# PIC16F1613 register map
Vendor: Microchip
Registers are 8-bit, read-write, reset 0x0 unless marked. A register's access mark holds for its fields unless they carry their own. Addresses are absolute, and some are shared; only a register's first bit layout is shown; [hi:lo] are bit positions; {n}, {i} and the like mark numbered series.

## SFR
0x00 INDF0 reset not defined — (power-on value xxxxxxxx)
0x01 INDF1 reset not defined — (power-on value xxxxxxxx)
0x02 PCL
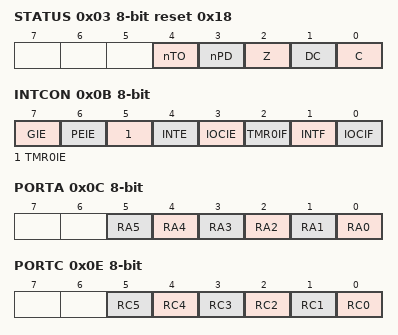
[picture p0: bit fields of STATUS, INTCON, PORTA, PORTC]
0x03 STATUS reset 0x18
  [4] nTO ro, [3] nPD ro, [2] Z, [1] DC, [0] C
0x04 FSR0L
0x05 FSR0H
0x06 FSR1L
0x07 FSR1H
0x08 BSR
  [4:0] BSR
0x09 WREG
  [7:0] WREG0
0x0A PCLATH
  [6:0] PCLATH
0x0B INTCON
  [7] GIE, [6] PEIE, [5] TMR0IE, [4] INTE, [3] IOCIE, [2] TMR0IF, [1] INTF, [0] IOCIF ro
0x0C PORTA reset not defined — (power-on value --xxxxxx)
  [n] RA{n} (n=0..5)
0x0E PORTC reset not defined — (power-on value --xxxxxx)
  [n] RC{n} (n=0..5)
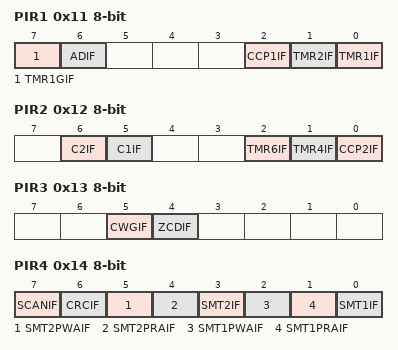
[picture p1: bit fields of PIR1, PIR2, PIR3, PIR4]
0x11 PIR1
  [7] TMR1GIF — Timer1 Gate Interrupt Flag bit
  [6] ADIF — A/D Converter Interrupt Flag bit
  [2] CCP1IF
  [1] TMR2IF — TMR2 to PR2 Match Interrupt Flag bit
  [0] TMR1IF — TMR1 Overflow Interrupt Flag bit
0x12 PIR2
  [6] C2IF — Numerically Controlled Oscillator Flag bit
  [5] C1IF — Numerically Controlled Oscillator Flag bit
  [2] TMR6IF — Numerically Controlled Oscillator Flag bit
  [1] TMR4IF
  [0] CCP2IF
0x13 PIR3
  [5] CWGIF, [4] ZCDIF
0x14 PIR4
  [7] SCANIF, [6] CRCIF, [5] SMT2PWAIF, [4] SMT2PRAIF, [3] SMT2IF, [2] SMT1PWAIF, [1] SMT1PRAIF, [0] SMT1IF
0x15 TMR0 reset not defined — (power-on value xxxxxxxx)
0x16 TMR1L reset not defined — (power-on value xxxxxxxx)
0x17 TMR1H reset not defined — (power-on value xxxxxxxx)
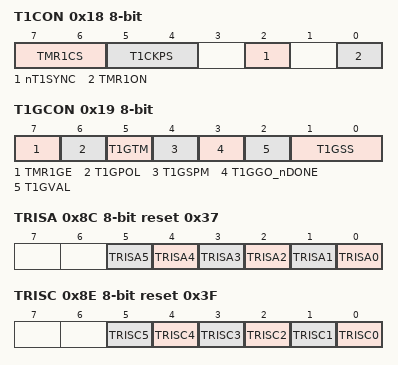
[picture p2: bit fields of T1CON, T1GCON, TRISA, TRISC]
0x18 T1CON
  [7:6] TMR1CS, [5:4] T1CKPS, [2] nT1SYNC, [0] TMR1ON
0x19 T1GCON reset not defined — (power-on value 00000x00)
  [7] TMR1GE, [6] T1GPOL, [5] T1GTM, [4] T1GSPM, [3] T1GGO_nDONE, [2] T1GVAL ro, [1:0] T1GSS
0x8C TRISA reset 0x37 — PORTA Data Direction Control Register
  [n] TRISA{n} (n=0..5)
0x8E TRISC reset 0x3F — PORTC Data Direction Control Register
  [n] TRISC{n} (n=0..5)
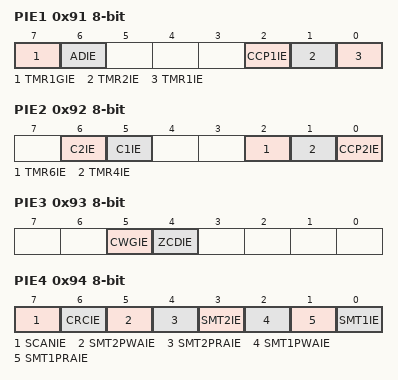
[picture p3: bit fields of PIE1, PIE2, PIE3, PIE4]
0x91 PIE1 — Peripheral Interrupt Enable Register 1
  [7] TMR1GIE — Timer1 Gate Interrupt Enable bit
  [6] ADIE — A/D Converter Interrupt Enable bit
  [2] CCP1IE
  [1] TMR2IE — TMR2 to PR2 Match Interrupt Enable bit
  [0] TMR1IE — TMR1 Overflow Interrupt Enable bit
0x92 PIE2 — Peripheral Interrupt Enable Register 2
  [6] C2IE, [5] C1IE, [2] TMR6IE, [1] TMR4IE, [0] CCP2IE
0x93 PIE3 — Peripheral Interrupt Enable Register 3
  [5] CWGIE, [4] ZCDIE
0x94 PIE4
  [7] SCANIE, [6] CRCIE, [5] SMT2PWAIE, [4] SMT2PRAIE, [3] SMT2IE, [2] SMT1PWAIE, [1] SMT1PRAIE, [0] SMT1IE
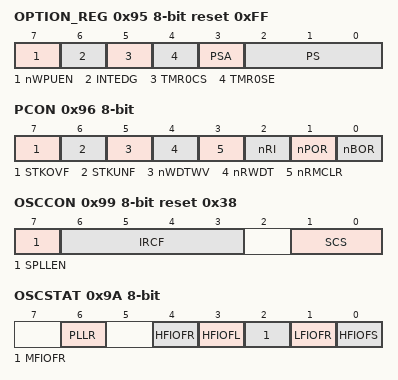
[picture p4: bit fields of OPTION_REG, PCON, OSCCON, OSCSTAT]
0x95 OPTION_REG reset 0xFF — Option Register
  [7] nWPUEN — Weak Pull-up Enable bit
  [6] INTEDG — Interrupt Edge Select bit
  [5] TMR0CS
  [4] TMR0SE — TMR0 Source Edge Select bit
  [3] PSA — Prescaler Active bit
  [2:0] PS
0x96 PCON reset not defined — Power Control Register (power-on value 001111qq)
  [7] STKOVF — Stack Overflow Flag bit
  [6] STKUNF — Stack Underflow Flag bit
  [5] nWDTWV
  [4] nRWDT
  [3] nRMCLR — MCLR Reset Flag bit
  [2] nRI — RESET Instruction Flag bit
  [1] nPOR — Power-on Reset Status bit
  [0] nBOR — Brown-out Reset Status bit
0x98 OSCTUNE
  [5:0] TUN
0x99 OSCCON reset 0x38 — Oscillator Control Register
  [7] SPLLEN, [6:3] IRCF, [1:0] SCS
0x9A OSCSTAT ro reset not defined — Oscillator Status Register (power-on value -0-00q00)
  [6] PLLR
  [4] HFIOFR
  [3] HFIOFL
  [2] MFIOFR
  [1] LFIOFR — Low Freqency Internal Oscillator Ready bit
  [0] HFIOFS — Low Freqency Internal Oscillator Ready bit
0x9B ADRESL reset not defined — A/D Result Register LSB (power-on value xxxxxxxx)
0x9C ADRESH reset not defined — A/D Result Register MSB (power-on value xxxxxxxx)
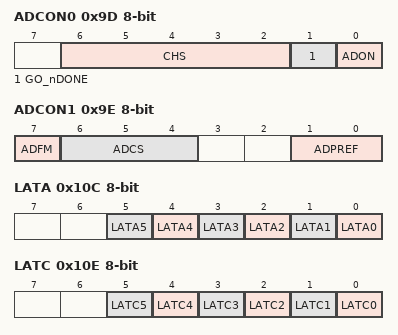
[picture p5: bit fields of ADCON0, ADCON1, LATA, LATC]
0x9D ADCON0 — Analog-to-Digital Control Register 0
  [6:2] CHS
  [1] GO_nDONE — A/D Conversion Status bit
  [0] ADON — A/D Module Enable bit
0x9E ADCON1 — Analog-to-Digital Control Register 1
  [7] ADFM — A/D Result Format Select bit
  [6:4] ADCS
  [1:0] ADPREF
0x9F ADCON2 — Analog-to-Digital Control Register 2
  [7:4] TRIGSEL
0x10C LATA reset not defined — (power-on value --xxxxxx)
  [n] LATA{n} (n=0..5)
0x10E LATC reset not defined — (power-on value --xxxxxx)
  [n] LATC{n} (n=0..5)
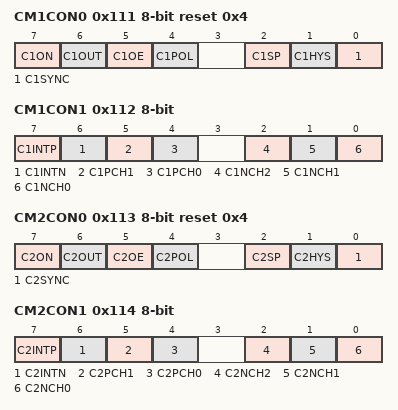
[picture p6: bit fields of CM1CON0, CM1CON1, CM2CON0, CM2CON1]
0x111 CM1CON0 reset 0x4
  [7] C1ON — Comparator Enable bit
  [6] C1OUT ro — Comparator Output bit
  [5] C1OE — Comparator Output Enable bit
  [4] C1POL — Comparator Output Polarity Select bit
  [2] C1SP — Comparator Speed/Power Select bit
  [1] C1HYS — Comparator Hysteresis Enable bit
  [0] C1SYNC — Comparator Output Synchronous Mode bit
0x112 CM1CON1
  [7] C1INTP — Comparator Interrupt on Positive going edge Enable bits
  [6] C1INTN — Comparator Interrupt on Negative going edge Enable bits
  [5] C1PCH1 — Comparator Positive Input Channel Select bits
  [4] C1PCH0 — Comparator Positive Input Channel Select bits
  [2] C1NCH2
  [1] C1NCH1 — Comparator Negative Input Channel Select bits
  [0] C1NCH0 — Comparator Negative Input Channel Select bits
0x113 CM2CON0 reset 0x4
  [7] C2ON, [6] C2OUT ro, [5] C2OE, [4] C2POL, [2] C2SP, [1] C2HYS, [0] C2SYNC
0x114 CM2CON1
  [7] C2INTP — Comparator Interrupt on Positive going edge Enable bits
  [6] C2INTN — Comparator Interrupt on Negative going edge Enable bits
  [5] C2PCH1 — Comparator Positive Input Channel Select bits
  [4] C2PCH0 — Comparator Positive Input Channel Select bits
  [2] C2NCH2
  [1] C2NCH1 — Comparator Negative Input Channel Select bits
  [0] C2NCH0 — Comparator Negative Input Channel Select bits
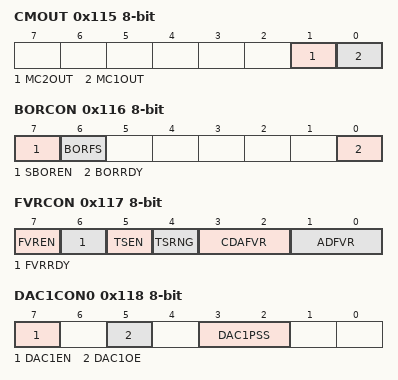
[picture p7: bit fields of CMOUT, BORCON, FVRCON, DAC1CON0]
0x115 CMOUT ro — Comparator Output Register
  [1] MC2OUT, [0] MC1OUT
0x116 BORCON reset not defined — Brown-out Reset Control Register (power-on value 10-----q)
  [7] SBOREN — Software Brown Out Reset Enable bit
  [6] BORFS
  [0] BORRDY ro — Brown-out Reset Circuit Ready Status bit
0x117 FVRCON reset not defined — Voltage Reference Control Register 0 (power-on value 0q00xx00)
  [7] FVREN — Fixed Voltage Reference Enable
  [6] FVRRDY ro — Fixed Voltage Reference Ready Flag
  [5] TSEN — Temperature Sensor Enable
  [4] TSRNG — Temperature Sensor Range Select
  [3:2] CDAFVR
  [1:0] ADFVR — A/D Converter Fixed Voltage Reference Selection
0x118 DAC1CON0 — Voltage Reference Control Register 0
  [7] DAC1EN — DAC 1 Enable bit
  [5] DAC1OE
  [3:2] DAC1PSS
0x119 DAC1CON1 — Voltage Reference Control Register 1
  [7:0] DAC1R
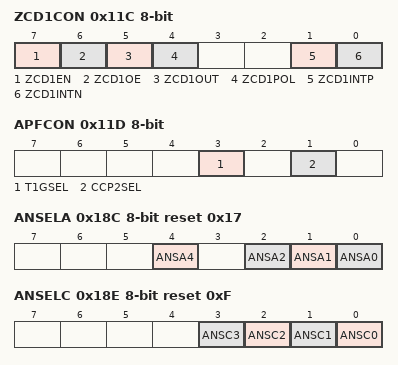
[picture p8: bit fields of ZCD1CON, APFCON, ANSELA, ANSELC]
0x11C ZCD1CON reset not defined — (power-on value 00x0--00)
  [7] ZCD1EN, [6] ZCD1OE, [5] ZCD1OUT ro, [4] ZCD1POL, [1] ZCD1INTP, [0] ZCD1INTN
0x11D APFCON — Alternate Pin Function Control Register
  [3] T1GSEL, [1] CCP2SEL
0x18C ANSELA reset 0x17
  [4] ANSA4, [2] ANSA2, [1] ANSA1, [0] ANSA0
0x18E ANSELC reset 0xF
  [n] ANSC{n} (n=0..3)
0x191 PMADRL
0x192 PMADRH reset 0x80
  [6:0] PMADRH
0x193 PMDATL reset not defined — (power-on value xxxxxxxx)
0x194 PMDATH reset not defined — (power-on value --xxxxxx)
  [5:0] PMDATH
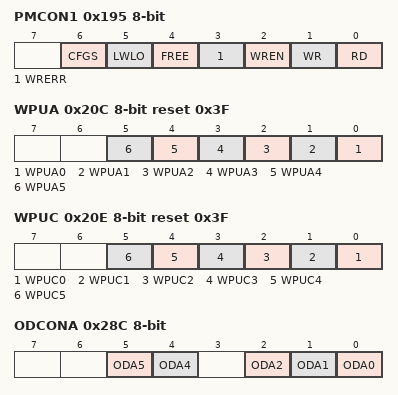
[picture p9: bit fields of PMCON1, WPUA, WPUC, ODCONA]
0x195 PMCON1 reset not defined — (power-on value -000x000)
  [6] CFGS — FLASH Program / Data EEPROM or Configuration Select bit
  [5] LWLO — Load Write Latches Only bit
  [4] FREE — Program FLASH Erase Enable bit
  [3] WRERR — Sequence Error Flag bit
  [2] WREN — Program/Erase Enable bit
  [1] WR — Write Control bit (can only be set)
  [0] RD — Read Control bit (can only be set)
0x196 PMCON2 wo
0x197 VREGCON reset 0x1
  [1:0] VREGPM
0x20C WPUA reset 0x3F
  [n] WPUA{n} (n=0..5)
0x20E WPUC reset 0x3F
  [n] WPUC{n} (n=0..5)
0x28C ODCONA
  [5] ODA5, [4] ODA4, [2] ODA2, [1] ODA1, [0] ODA0
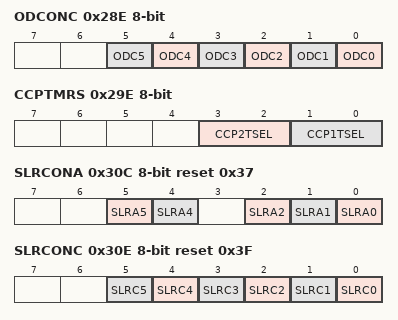
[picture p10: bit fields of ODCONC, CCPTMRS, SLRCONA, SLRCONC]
0x28E ODCONC
  [n] ODC{n} (n=0..5)
0x29E CCPTMRS
  [3:2] CCP2TSEL, [1:0] CCP1TSEL
0x30C SLRCONA reset 0x37
  [5] SLRA5, [4] SLRA4, [2] SLRA2, [1] SLRA1, [0] SLRA0
0x30E SLRCONC reset 0x3F
  [n] SLRC{n} (n=0..5)
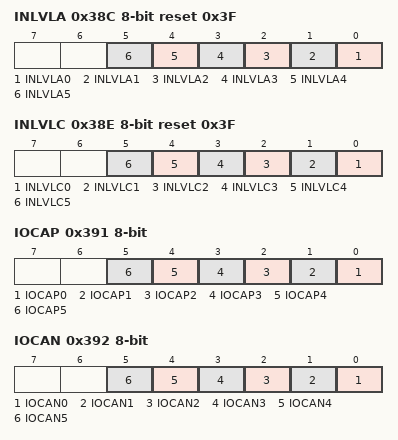
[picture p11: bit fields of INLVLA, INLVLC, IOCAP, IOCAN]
0x38C INLVLA reset 0x3F
  [n] INLVLA{n} (n=0..5)
0x38E INLVLC reset 0x3F
  [n] INLVLC{n} (n=0..5)
0x391 IOCAP
  [n] IOCAP{n} (n=0..5)
0x392 IOCAN
  [n] IOCAN{n} (n=0..5)
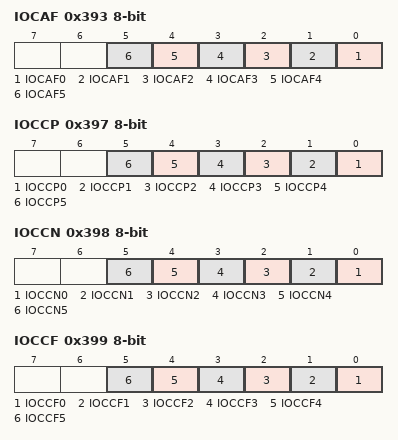
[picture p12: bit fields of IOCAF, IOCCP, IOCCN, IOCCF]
0x393 IOCAF
  [n] IOCAF{n} (n=0..5)
0x397 IOCCP
  [n] IOCCP{n} (n=0..5)
0x398 IOCCN
  [n] IOCCN{n} (n=0..5)
0x399 IOCCF
  [n] IOCCF{n} (n=0..5)
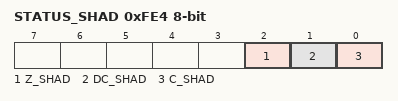
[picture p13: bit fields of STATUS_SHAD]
0xFE4 STATUS_SHAD reset not defined — (power-on value -----xxx)
  [2] Z_SHAD, [1] DC_SHAD, [0] C_SHAD
0xFE5 WREG_SHAD reset not defined — (power-on value xxxxxxxx)
0xFE6 BSR_SHAD reset not defined — (power-on value ---xxxxx)
  [4:0] BSR_SHAD
0xFE7 PCLATH_SHAD reset not defined — (power-on value -xxxxxxx)
  [6:0] PCLATH_SHAD
0xFE8 FSR0L_SHAD reset not defined — (power-on value xxxxxxxx)
0xFE9 FSR0H_SHAD reset not defined — (power-on value xxxxxxxx)
0xFEA FSR1L_SHAD reset not defined — (power-on value xxxxxxxx)
0xFEB FSR1H_SHAD reset not defined — (power-on value xxxxxxxx)
0xFED STKPTR reset 0x1F
  [4:0] STKPTR
0xFEE TOSL reset not defined — (power-on value xxxxxxxx)
0xFEF TOSH reset not defined — (power-on value -xxxxxxx)
  [6:0] TOSH
